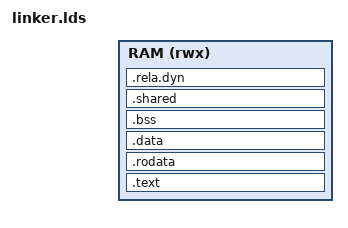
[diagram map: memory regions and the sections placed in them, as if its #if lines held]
/*
 * SPDX-License-Identifier: BSD-3-Clause
 * SPDX-FileCopyrightText: Copyright TF-RMM Contributors.
 */

#include <sizes.h>
#include <utils_def.h>
#include <xlat_high_va.h>

#if (GRANULE_SIZE == 0)
#error "Required config options not set for the linker script."
#endif

ENTRY(el0_app_entry)

#define APP_VA_START	(UL(0xffffffffffffffff) - XLAT_HIGH_VA_SIZE + 1)

#define EL0_APP_TEXT_START	(APP_VA_START + (2*4096)) /* leave some va space for the app_reg_ctx area */

MEMORY {
	/* The length value is specified as XLAT_HIGH_VA_SIZE -1 as it seems
	 * that the llvm linker cannot handle if the last byte is the region is
	 * UINT64_MAX.
	 */
	RAM (rwx): ORIGIN = APP_VA_START, LENGTH = XLAT_HIGH_VA_SIZE - 1
}

SECTIONS
{
	.text EL0_APP_TEXT_START : {
		*app_helpers.S.obj(.text*)
		*(.text*)
		. = ALIGN(GRANULE_SIZE);
	} >RAM

	.rodata ALIGN(GRANULE_SIZE) : {
		*(.rodata*)
		*(.got*)
		. = ALIGN(GRANULE_SIZE);
	} >RAM

	.data ALIGN(GRANULE_SIZE) : {
		*(.data*)
		. = ALIGN(GRANULE_SIZE);
	} >RAM

	.bss ALIGN(GRANULE_SIZE) (NOLOAD) : {
		*(.bss*)
		. = ALIGN(GRANULE_SIZE);
	} >RAM

	.shared ALIGN(GRANULE_SIZE) (NOLOAD) : {
		el0_app_shared_start = .;
		. = . + (GRANULE_SIZE);
		el0_app_shared_end = .;
	} >RAM

	/*
	 * Add this section (although not used) to make sure that it is not
	 * generated by the linker in between other sections used by the app
	 */
	.rela.dyn ALIGN(8) : {
		*(.rela*)
	} >RAM

	/DISCARD/ : { *(.dynstr*) }
	/DISCARD/ : { *(.dynsym*) }
	/DISCARD/ : { *(.dynamic*) }
	/DISCARD/ : { *(.gnu*) }
	/DISCARD/ : { *(.hash*) }
	/DISCARD/ : { *(.interp*) }
	/DISCARD/ : { *(.note*) }
	/DISCARD/ : { *(.plt*) }
}
